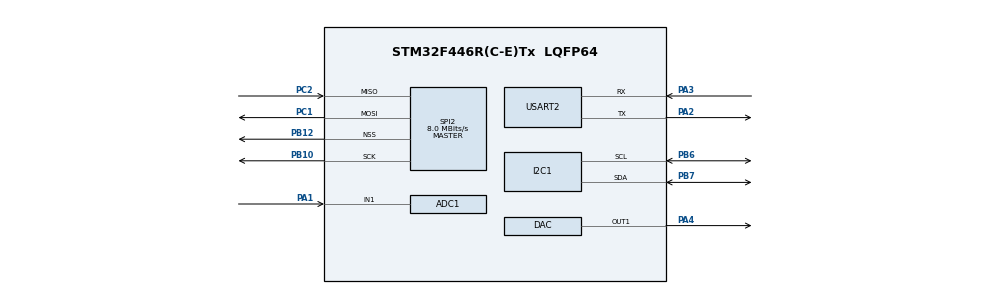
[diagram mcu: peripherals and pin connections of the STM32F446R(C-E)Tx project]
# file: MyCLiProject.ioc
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ADC1.Channel-2\#ChannelRegularConversion=ADC_CHANNEL_1
ADC1.NbrOfConversionFlag=1
ADC1.Rank-2\#ChannelRegularConversion=1
ADC1.SamplingTime-2\#ChannelRegularConversion=ADC_SAMPLETIME_3CYCLES
ADC1.master=1
Dma.ADC1.1.Direction=DMA_PERIPH_TO_MEMORY
Dma.ADC1.1.FIFOMode=DMA_FIFOMODE_DISABLE
Dma.ADC1.1.Instance=DMA2_Stream4
Dma.ADC1.1.MemDataAlignment=DMA_MDATAALIGN_HALFWORD
Dma.ADC1.1.MemInc=DMA_MINC_ENABLE
Dma.ADC1.1.Mode=DMA_NORMAL
Dma.ADC1.1.PeriphDataAlignment=DMA_PDATAALIGN_HALFWORD
Dma.ADC1.1.PeriphInc=DMA_PINC_DISABLE
Dma.ADC1.1.Priority=DMA_PRIORITY_LOW
Dma.DAC1.0.Direction=DMA_MEMORY_TO_PERIPH
Dma.DAC1.0.FIFOMode=DMA_FIFOMODE_DISABLE
Dma.DAC1.0.Instance=DMA1_Stream5
Dma.DAC1.0.MemDataAlignment=DMA_MDATAALIGN_HALFWORD
Dma.DAC1.0.MemInc=DMA_MINC_ENABLE
Dma.DAC1.0.Mode=DMA_NORMAL
Dma.DAC1.0.PeriphDataAlignment=DMA_PDATAALIGN_HALFWORD
Dma.DAC1.0.PeriphInc=DMA_PINC_DISABLE
Dma.DAC1.0.Priority=DMA_PRIORITY_LOW
Dma.Request0=DAC1
Dma.Request1=ADC1
FREERTOS.Tasks01=defaultTask,24,128,StartDefaultTask,Default,NULL,Dynamic,NULL,NULL
Mcu.Family=STM32F4
Mcu.Name=STM32F446R(C-E)Tx
Mcu.Package=LQFP64
NVIC.DMA1_Stream5_IRQn=true\:5\:0\:false\:false\:true\:true\:false\:true\:true
NVIC.DMA2_Stream4_IRQn=true\:5\:0\:false\:false\:true\:false\:false\:true\:true
NVIC.I2C1_ER_IRQn=true\:5\:0\:false\:false\:true\:true\:true\:true\:true
NVIC.I2C1_EV_IRQn=true\:5\:0\:false\:false\:true\:true\:true\:true\:true
NVIC.PriorityGroup=NVIC_PRIORITYGROUP_4
NVIC.SPI2_IRQn=true\:5\:0\:false\:false\:true\:true\:true\:true\:true
NVIC.TIM6_DAC_IRQn=true\:15\:0\:false\:false\:true\:false\:true\:true\:true
NVIC.TimeBase=TIM6_DAC_IRQn
NVIC.TimeBaseIP=TIM6
NVIC.USART2_IRQn=true\:5\:0\:false\:false\:true\:true\:true\:true\:true
PA0-WKUP.Mode=SYS_WakeUp0
PA0-WKUP.Signal=SYS_WKUP0
PA1.Signal=ADCx_IN1
PA2.Mode=Asynchronous
PA2.Signal=USART2_TX
PA3.Mode=Asynchronous
PA3.Signal=USART2_RX
PA4.Signal=COMP_DAC1_group
PB10.Mode=Full_Duplex_Master
PB10.Signal=SPI2_SCK
PB12.Mode=NSS_Signal_Hard_Output
PB12.Signal=SPI2_NSS
PB6.Mode=I2C
PB6.Signal=I2C1_SCL
PB7.Mode=I2C
PB7.Signal=I2C1_SDA
PC1.Mode=Full_Duplex_Master
PC1.Signal=SPI2_MOSI
PC2.Mode=Full_Duplex_Master
PC2.Signal=SPI2_MISO
ProjectManager.HeapSize=0x200
ProjectManager.StackSize=0x400
ProjectManager.TargetToolchain=STM32CubeIDE
RCC.CortexFreq_Value=16000000
RCC.USBFreq_Value=96000000
RCC.VCOOutputFreq_Value=192000000
SH.ADCx_IN1.0=ADC1_IN1,IN1
SH.COMP_DAC1_group.0=DAC_OUT1,DAC_OUT1
SPI2.CalculateBaudRate=8.0 MBits/s
SPI2.Direction=SPI_DIRECTION_2LINES
SPI2.Mode=SPI_MODE_MASTER
SPI2.VirtualNSS=VM_NSSHARD
SPI2.VirtualType=VM_MASTER
USART2.VirtualMode=VM_ASYNC
VP_FREERTOS_VS_CMSIS_V2.Mode=CMSIS_V2
VP_SYS_VS_tim6.Mode=TIM6
VP_TIM3_VS_ClockSourceITR.Mode=TriggerSource_ITR0
VP_TIM3_VS_ControllerModeTrigger.Mode=Trigger Mode
board=custom

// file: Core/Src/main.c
#include "stdio.h"
#include "string.h"
#include "stdint.h"
#include <stdbool.h>

#include "main.h"
#include "cmsis_os.h"
#include "FreeRTOS_CLI.h"

void SystemClock_Config(void);
void MX_FREERTOS_Init(void);
void MX_USART2_UART_Init(void);
void StartDefaultTask(void *argument);
void write_register(unsigned int addr, unsigned int val);

/* ------------------------Private variables -----------------------------------------------*/

UART_HandleTypeDef huart2;
extern bool xGpioMutex = true;

/* -----------------------Definitions for defaultTask -------------------------------------- */
osThreadId_t defaultTaskHandle;

const osThreadAttr_t defaultTask_attributes = {
  .name = "defaultTask",
  .stack_size = 128 * 4,
  .priority = (osPriority_t) osPriorityNormal,
};

/* --------------UART input/output configuration---------------------------------------------*/
#define PUTCHAR_PROTOTYPE int __io_putchar(int ch)
#define GETCHAR_PROTOTYPE int __io_getchar(void)

PUTCHAR_PROTOTYPE
{

	HAL_UART_Transmit(&huart2, (uint8_t*)&ch, 1,0xFFFF);
  return ch;
}

GETCHAR_PROTOTYPE
{
  uint8_t ch = 0;
  __HAL_UART_CLEAR_OREFLAG(&huart2);
  HAL_UART_Receive (&huart2, (uint8_t *)&ch, 1, HAL_MAX_DELAY);
  return ch;

}

/* ==================================START OF MAIN ROUTINE=============================================== */

int main(void)
{

  HAL_Init();
  SystemClock_Config();
  MX_GPIO_Init();
  MX_I2C1_Init();
  MX_ADC1_Init();
  MX_DAC_Init();
  MX_TIM3_Init();
  MX_SPI2_Init();
  MX_USART2_UART_Init();
  vRegisterCLICommands();
  osKernelInitialize();

  write_register (0x4002040c,0x5100); // required for setting I2C #1 pins with internal pull ups
  write_register (0x40020000,0xA80087AC);  // configuring PA5 pin to GPIO

  printf("\r\n<<<<<<<Hello from STM32F446RTE MCU UART (RTOS) terminal>>>>>\r\n");

  defaultTaskHandle = osThreadNew(StartDefaultTask, NULL, &defaultTask_attributes);

  vUARTCommandConsoleStart(configUART_COMMAND_CONSOLE_STACK_SIZE,configUART_COMMAND_CONSOLE_TASK_PRIORITY);

  osKernelStart();

  while(1){}

}

/* ==================================END OF MAIN ROUTINE================================================= */

/* ----------------------------------AUX functions------------------------*/

void SystemClock_Config(void)
{
  RCC_OscInitTypeDef RCC_OscInitStruct = {0};
  RCC_ClkInitTypeDef RCC_ClkInitStruct = {0};

  /** Configure the main internal regulator output voltage
  */
  __HAL_RCC_PWR_CLK_ENABLE();
  __HAL_PWR_VOLTAGESCALING_CONFIG(PWR_REGULATOR_VOLTAGE_SCALE3);

  /** Initializes the RCC Oscillators according to the specified parameters
  * in the RCC_OscInitTypeDef structure.
  */
  RCC_OscInitStruct.OscillatorType = RCC_OSCILLATORTYPE_HSI;
  RCC_OscInitStruct.HSIState = RCC_HSI_ON;
  RCC_OscInitStruct.HSICalibrationValue = RCC_HSICALIBRATION_DEFAULT;
  RCC_OscInitStruct.PLL.PLLState = RCC_PLL_NONE;
  if (HAL_RCC_OscConfig(&RCC_OscInitStruct) != HAL_OK)
  {
    Error_Handler();
  }

  /** Initializes the CPU, AHB and APB buses clocks
  */
  RCC_ClkInitStruct.ClockType = RCC_CLOCKTYPE_HCLK|RCC_CLOCKTYPE_SYSCLK
                              |RCC_CLOCKTYPE_PCLK1|RCC_CLOCKTYPE_PCLK2;
  RCC_ClkInitStruct.SYSCLKSource = RCC_SYSCLKSOURCE_HSI;
  RCC_ClkInitStruct.AHBCLKDivider = RCC_SYSCLK_DIV1;
  RCC_ClkInitStruct.APB1CLKDivider = RCC_HCLK_DIV1;
  RCC_ClkInitStruct.APB2CLKDivider = RCC_HCLK_DIV1;

  if (HAL_RCC_ClockConfig(&RCC_ClkInitStruct, FLASH_LATENCY_0) != HAL_OK)
  {
    Error_Handler();
  }
}

void HAL_TIM_PeriodElapsedCallback(TIM_HandleTypeDef *htim)
{
  if (htim->Instance == TIM6) {
    HAL_IncTick();
  }
}

void StartDefaultTask(void *argument)
{
  /* USER CODE BEGIN 5 */
  GPIO_PinState PinState = GPIO_PIN_SET;

  /* Infinite loop */

      for(;;)
      {
          if (xGpioMutex == true) {
          PinState = !PinState;
          }
          HAL_GPIO_WritePin(LD2_GPIO_Port, LD2_Pin, PinState);
          osDelay(1000);

      }

  /* USER CODE END 5 */
}

void Error_Handler(void)
{
  __disable_irq();
  while (1)
  {
  }
}

void write_register(unsigned int addr, unsigned int val)
{

	*((unsigned int *)addr)=((unsigned int *)val);

}
